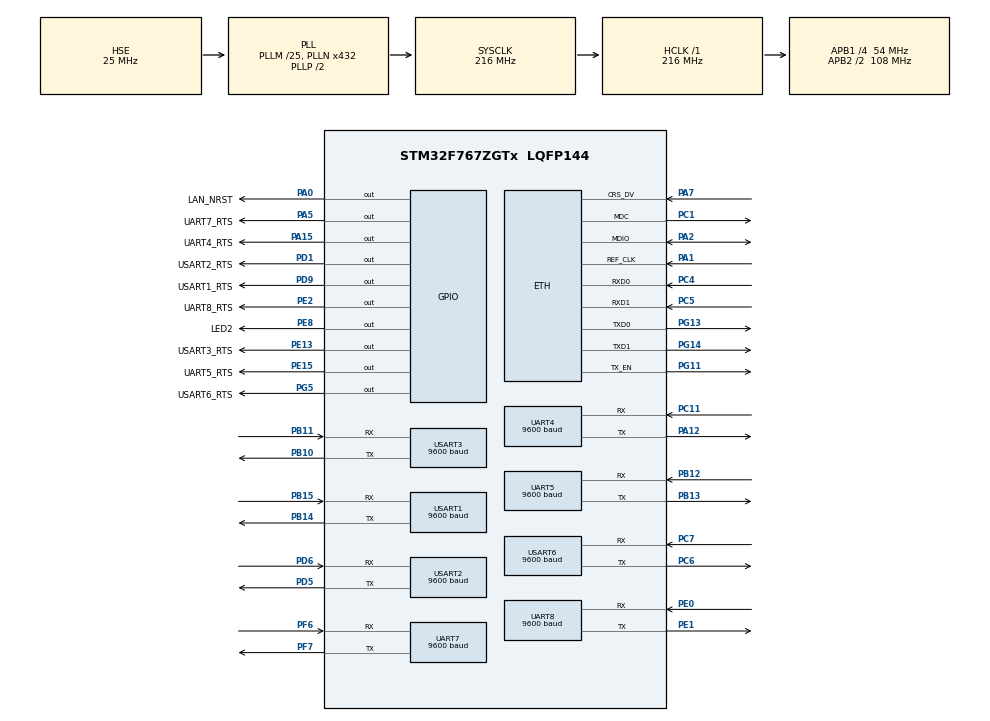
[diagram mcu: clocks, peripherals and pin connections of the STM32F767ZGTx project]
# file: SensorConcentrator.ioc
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CORTEX_M7.ART_ACCELERATOR_ENABLE=1
CORTEX_M7.AccessPermission_Spec=MPU_REGION_FULL_ACCESS
CORTEX_M7.BaseAddress_Spec=0x20000000
CORTEX_M7.CPU_DCache=Enabled
CORTEX_M7.CPU_ICache=Enabled
CORTEX_M7.DisableExec_Spec=MPU_INSTRUCTION_ACCESS_ENABLE
CORTEX_M7.Enable_S-Cortex_Memory_Protection_Unit_Region1_Settings_S=__NULL
CORTEX_M7.Enable_S-Cortex_Memory_Protection_Unit_Region2_Settings_S=__NULL
CORTEX_M7.IsBufferable_Spec=MPU_ACCESS_NOT_BUFFERABLE
CORTEX_M7.IsCacheable_Spec=MPU_ACCESS_NOT_CACHEABLE
CORTEX_M7.IsShareable_Spec=MPU_ACCESS_SHAREABLE
CORTEX_M7.Size_Spec=MPU_REGION_SIZE_512KB
CORTEX_M7.SubRegionDisable_Spec=0x00
CORTEX_M7.TypeExtField_Spec=MPU_TEX_LEVEL1
CORTEX_M7.default_mode_Activation=1
Dma.Request0=USART1_RX
Dma.Request1=USART1_TX
Dma.Request10=UART5_RX
Dma.Request11=UART5_TX
Dma.Request2=USART2_RX
Dma.Request3=USART2_TX
Dma.Request4=USART3_RX
Dma.Request5=USART3_TX
Dma.Request6=USART6_RX
Dma.Request7=USART6_TX
Dma.Request8=UART4_RX
Dma.Request9=UART4_TX
Dma.UART4_RX.8.Direction=DMA_PERIPH_TO_MEMORY
Dma.UART4_RX.8.FIFOMode=DMA_FIFOMODE_DISABLE
Dma.UART4_RX.8.Instance=DMA1_Stream2
Dma.UART4_RX.8.MemDataAlignment=DMA_MDATAALIGN_BYTE
Dma.UART4_RX.8.MemInc=DMA_MINC_ENABLE
Dma.UART4_RX.8.Mode=DMA_CIRCULAR
Dma.UART4_RX.8.PeriphDataAlignment=DMA_PDATAALIGN_BYTE
Dma.UART4_RX.8.PeriphInc=DMA_PINC_DISABLE
Dma.UART4_RX.8.Priority=DMA_PRIORITY_LOW
Dma.UART4_TX.9.Direction=DMA_MEMORY_TO_PERIPH
Dma.UART4_TX.9.FIFOMode=DMA_FIFOMODE_DISABLE
Dma.UART4_TX.9.Instance=DMA1_Stream4
Dma.UART4_TX.9.MemDataAlignment=DMA_MDATAALIGN_BYTE
Dma.UART4_TX.9.MemInc=DMA_MINC_ENABLE
Dma.UART4_TX.9.Mode=DMA_NORMAL
Dma.UART4_TX.9.PeriphDataAlignment=DMA_PDATAALIGN_BYTE
Dma.UART4_TX.9.PeriphInc=DMA_PINC_DISABLE
Dma.UART4_TX.9.Priority=DMA_PRIORITY_LOW
Dma.UART5_RX.10.Direction=DMA_PERIPH_TO_MEMORY
Dma.UART5_RX.10.FIFOMode=DMA_FIFOMODE_DISABLE
Dma.UART5_RX.10.Instance=DMA1_Stream0
Dma.UART5_RX.10.MemDataAlignment=DMA_MDATAALIGN_BYTE
Dma.UART5_RX.10.MemInc=DMA_MINC_ENABLE
Dma.UART5_RX.10.Mode=DMA_CIRCULAR
Dma.UART5_RX.10.PeriphDataAlignment=DMA_PDATAALIGN_BYTE
Dma.UART5_RX.10.PeriphInc=DMA_PINC_DISABLE
Dma.UART5_RX.10.Priority=DMA_PRIORITY_LOW
Dma.UART5_TX.11.Direction=DMA_MEMORY_TO_PERIPH
Dma.UART5_TX.11.FIFOMode=DMA_FIFOMODE_DISABLE
Dma.UART5_TX.11.Instance=DMA1_Stream7
Dma.UART5_TX.11.MemDataAlignment=DMA_MDATAALIGN_BYTE
Dma.UART5_TX.11.MemInc=DMA_MINC_ENABLE
Dma.UART5_TX.11.Mode=DMA_NORMAL
Dma.UART5_TX.11.PeriphDataAlignment=DMA_PDATAALIGN_BYTE
Dma.UART5_TX.11.PeriphInc=DMA_PINC_DISABLE
Dma.UART5_TX.11.Priority=DMA_PRIORITY_LOW
Dma.USART1_RX.0.Direction=DMA_PERIPH_TO_MEMORY
Dma.USART1_RX.0.FIFOMode=DMA_FIFOMODE_DISABLE
Dma.USART1_RX.0.Instance=DMA2_Stream2
Dma.USART1_RX.0.MemDataAlignment=DMA_MDATAALIGN_BYTE
Dma.USART1_RX.0.MemInc=DMA_MINC_ENABLE
Dma.USART1_RX.0.Mode=DMA_CIRCULAR
Dma.USART1_RX.0.PeriphDataAlignment=DMA_PDATAALIGN_BYTE
Dma.USART1_RX.0.PeriphInc=DMA_PINC_DISABLE
Dma.USART1_RX.0.Priority=DMA_PRIORITY_LOW
Dma.USART1_TX.1.Direction=DMA_MEMORY_TO_PERIPH
Dma.USART1_TX.1.FIFOMode=DMA_FIFOMODE_DISABLE
Dma.USART1_TX.1.Instance=DMA2_Stream7
Dma.USART1_TX.1.MemDataAlignment=DMA_MDATAALIGN_BYTE
Dma.USART1_TX.1.MemInc=DMA_MINC_ENABLE
Dma.USART1_TX.1.Mode=DMA_NORMAL
Dma.USART1_TX.1.PeriphDataAlignment=DMA_PDATAALIGN_BYTE
Dma.USART1_TX.1.PeriphInc=DMA_PINC_DISABLE
Dma.USART1_TX.1.Priority=DMA_PRIORITY_LOW
Dma.USART2_RX.2.Direction=DMA_PERIPH_TO_MEMORY
Dma.USART2_RX.2.FIFOMode=DMA_FIFOMODE_DISABLE
Dma.USART2_RX.2.Instance=DMA1_Stream5
Dma.USART2_RX.2.MemDataAlignment=DMA_MDATAALIGN_BYTE
Dma.USART2_RX.2.MemInc=DMA_MINC_ENABLE
Dma.USART2_RX.2.Mode=DMA_CIRCULAR
Dma.USART2_RX.2.PeriphDataAlignment=DMA_PDATAALIGN_BYTE
Dma.USART2_RX.2.PeriphInc=DMA_PINC_DISABLE
Dma.USART2_RX.2.Priority=DMA_PRIORITY_LOW
Dma.USART2_TX.3.Direction=DMA_MEMORY_TO_PERIPH
Dma.USART2_TX.3.FIFOMode=DMA_FIFOMODE_DISABLE
Dma.USART2_TX.3.Instance=DMA1_Stream6
Dma.USART2_TX.3.MemDataAlignment=DMA_MDATAALIGN_BYTE
Dma.USART2_TX.3.MemInc=DMA_MINC_ENABLE
Dma.USART2_TX.3.Mode=DMA_NORMAL
Dma.USART2_TX.3.PeriphDataAlignment=DMA_PDATAALIGN_BYTE
Dma.USART2_TX.3.PeriphInc=DMA_PINC_DISABLE
Dma.USART2_TX.3.Priority=DMA_PRIORITY_LOW
Dma.USART3_RX.4.Direction=DMA_PERIPH_TO_MEMORY
Dma.USART3_RX.4.FIFOMode=DMA_FIFOMODE_DISABLE
Dma.USART3_RX.4.Instance=DMA1_Stream1
Dma.USART3_RX.4.MemDataAlignment=DMA_MDATAALIGN_BYTE
Dma.USART3_RX.4.MemInc=DMA_MINC_ENABLE
Dma.USART3_RX.4.Mode=DMA_CIRCULAR
Dma.USART3_RX.4.PeriphDataAlignment=DMA_PDATAALIGN_BYTE
Dma.USART3_RX.4.PeriphInc=DMA_PINC_DISABLE
Dma.USART3_RX.4.Priority=DMA_PRIORITY_LOW
Dma.USART3_TX.5.Direction=DMA_MEMORY_TO_PERIPH
Dma.USART3_TX.5.FIFOMode=DMA_FIFOMODE_DISABLE
Dma.USART3_TX.5.Instance=DMA1_Stream3
Dma.USART3_TX.5.MemDataAlignment=DMA_MDATAALIGN_BYTE
Dma.USART3_TX.5.MemInc=DMA_MINC_ENABLE
Dma.USART3_TX.5.Mode=DMA_NORMAL
Dma.USART3_TX.5.PeriphDataAlignment=DMA_PDATAALIGN_BYTE
Dma.USART3_TX.5.PeriphInc=DMA_PINC_DISABLE
Dma.USART3_TX.5.Priority=DMA_PRIORITY_LOW
Dma.USART6_RX.6.Direction=DMA_PERIPH_TO_MEMORY
Dma.USART6_RX.6.FIFOMode=DMA_FIFOMODE_DISABLE
Dma.USART6_RX.6.Instance=DMA2_Stream1
Dma.USART6_RX.6.MemDataAlignment=DMA_MDATAALIGN_BYTE
Dma.USART6_RX.6.MemInc=DMA_MINC_ENABLE
Dma.USART6_RX.6.Mode=DMA_CIRCULAR
Dma.USART6_RX.6.PeriphDataAlignment=DMA_PDATAALIGN_BYTE
Dma.USART6_RX.6.PeriphInc=DMA_PINC_DISABLE
Dma.USART6_RX.6.Priority=DMA_PRIORITY_LOW
Dma.USART6_TX.7.Direction=DMA_MEMORY_TO_PERIPH
Dma.USART6_TX.7.FIFOMode=DMA_FIFOMODE_DISABLE
Dma.USART6_TX.7.Instance=DMA2_Stream6
Dma.USART6_TX.7.MemDataAlignment=DMA_MDATAALIGN_BYTE
Dma.USART6_TX.7.MemInc=DMA_MINC_ENABLE
Dma.USART6_TX.7.Mode=DMA_NORMAL
Dma.USART6_TX.7.PeriphDataAlignment=DMA_PDATAALIGN_BYTE
Dma.USART6_TX.7.PeriphInc=DMA_PINC_DISABLE
Dma.USART6_TX.7.Priority=DMA_PRIORITY_LOW
ETH.ETH_RX_DESC_CNT=8
ETH.ETH_TX_DESC_CNT=8
ETH.MediaInterface=HAL_ETH_RMII_MODE
ETH.RxDescAddress=0x20010200
ETH.TxDescAddress=0x20010000
FREERTOS.INCLUDE_pcTaskGetTaskName=1
FREERTOS.INCLUDE_uxTaskGetStackHighWaterMark=1
FREERTOS.INCLUDE_uxTaskGetStackHighWaterMark2=1
FREERTOS.INCLUDE_vTaskDelayUntil=1
FREERTOS.INCLUDE_xTaskGetCurrentTaskHandle=1
FREERTOS.Tasks01=defaultTask,0,1024,StartDefaultTask,Default,NULL,Dynamic,NULL,NULL
FREERTOS.configCHECK_FOR_STACK_OVERFLOW=2
FREERTOS.configENABLE_FPU=1
FREERTOS.configMAX_PRIORITIES=20
FREERTOS.configMINIMAL_STACK_SIZE=256
FREERTOS.configQUEUE_REGISTRY_SIZE=16
FREERTOS.configTIMER_QUEUE_LENGTH=16
FREERTOS.configTIMER_TASK_PRIORITY=4
FREERTOS.configTOTAL_HEAP_SIZE=102400
FREERTOS.configUSE_COUNTING_SEMAPHORES=1
FREERTOS.configUSE_MALLOC_FAILED_HOOK=1
FREERTOS.configUSE_RECURSIVE_MUTEXES=1
FREERTOS.configUSE_TIMERS=1
FREERTOS.configUSE_TRACE_FACILITY=1
IWDG.Prescaler=IWDG_PRESCALER_128
LWIP.BSP.number=1
LWIP.DEFAULT_THREAD_STACKSIZE=2048
LWIP.ETH_RX_BUFFER_CNT=32
LWIP.LWIP_DHCP=0
LWIP.LWIP_RAM_HEAP_POINTER=0x00000000
LWIP.LWIP_SNTP=1
LWIP.LWIP_TFTP=1
LWIP.MEMP_NUM_PBUF=64
LWIP.MEMP_NUM_TCP_SEG=24
LWIP.MEM_SIZE=24*1024
LWIP.PBUF_POOL_SIZE=32
LWIP.TCPIP_THREAD_STACKSIZE=4096
LWIP.TCP_SND_QUEUELEN=24
LWIP.Version=v2.1.2_Cube
LWIP0.BSP.STBoard=false
LWIP0.BSP.api=BSP_COMPONENT_DRIVER
LWIP0.BSP.component=LAN8742
LWIP0.BSP.instance=LAN8742
LWIP0.BSP.name=Driver_PHY
LWIP0.BSP.semaphore=S_LAN8742
LWIP0.BSP.solution=LAN8742
Mcu.Family=STM32F7
Mcu.Name=STM32F767ZGTx
Mcu.Package=LQFP144
NVIC.DMA1_Stream0_IRQn=true\:5\:0\:false\:false\:true\:true\:false\:true\:true
NVIC.DMA1_Stream1_IRQn=true\:5\:0\:false\:false\:true\:true\:false\:true\:true
NVIC.DMA1_Stream2_IRQn=true\:5\:0\:false\:false\:true\:true\:false\:true\:true
NVIC.DMA1_Stream3_IRQn=true\:5\:0\:false\:false\:true\:true\:false\:true\:true
NVIC.DMA1_Stream4_IRQn=true\:5\:0\:false\:false\:true\:true\:false\:true\:true
NVIC.DMA1_Stream5_IRQn=true\:5\:0\:false\:false\:true\:true\:false\:true\:true
NVIC.DMA1_Stream6_IRQn=true\:5\:0\:false\:false\:true\:true\:false\:true\:true
NVIC.DMA1_Stream7_IRQn=true\:5\:0\:false\:false\:true\:true\:false\:true\:true
NVIC.DMA2_Stream1_IRQn=true\:5\:0\:false\:false\:true\:true\:false\:true\:true
NVIC.DMA2_Stream2_IRQn=true\:5\:0\:false\:false\:true\:true\:false\:true\:true
NVIC.DMA2_Stream6_IRQn=true\:5\:0\:false\:false\:true\:true\:false\:true\:true
NVIC.DMA2_Stream7_IRQn=true\:5\:0\:false\:false\:true\:true\:false\:true\:true
NVIC.ETH_IRQn=true\:5\:0\:false\:false\:true\:true\:true\:true\:true
NVIC.PriorityGroup=NVIC_PRIORITYGROUP_4
NVIC.TIM7_IRQn=true\:15\:0\:false\:false\:true\:false\:false\:true\:true
NVIC.TimeBase=TIM7_IRQn
NVIC.TimeBaseIP=TIM7
NVIC.UART4_IRQn=true\:5\:0\:false\:false\:true\:true\:false\:true\:true
NVIC.UART5_IRQn=true\:5\:0\:false\:false\:true\:true\:false\:true\:true
NVIC.UART7_IRQn=true\:5\:0\:false\:false\:true\:true\:true\:true\:true
NVIC.UART8_IRQn=true\:5\:0\:false\:false\:true\:true\:false\:true\:true
NVIC.USART1_IRQn=true\:5\:0\:false\:false\:true\:true\:true\:true\:true
NVIC.USART2_IRQn=true\:5\:0\:false\:false\:true\:true\:false\:true\:true
NVIC.USART3_IRQn=true\:5\:0\:false\:false\:true\:true\:false\:true\:true
NVIC.USART6_IRQn=true\:5\:0\:false\:false\:true\:true\:false\:true\:true
PA0/WKUP.GPIO_Label=LAN_NRST
PA0/WKUP.GPIO_Speed=GPIO_SPEED_FREQ_LOW
PA0/WKUP.PinState=GPIO_PIN_SET
PA0/WKUP.Signal=GPIO_Output
PA1.Mode=RMII
PA1.Signal=ETH_REF_CLK
PA12.Mode=Asynchronous
PA12.Signal=UART4_TX
PA13.GPIO_Label=SWDIO
PA13.Mode=Serial_Wire
PA13.Signal=SYS_JTMS-SWDIO
PA14.GPIO_Label=SWCLK
PA14.Mode=Serial_Wire
PA14.Signal=SYS_JTCK-SWCLK
PA15.GPIO_Label=UART4_RTS
PA15.Signal=GPIO_Output
PA2.Mode=RMII
PA2.Signal=ETH_MDIO
PA5.GPIO_Label=UART7_RTS
PA5.Signal=GPIO_Output
PA7.Mode=RMII
PA7.Signal=ETH_CRS_DV
PB10.Mode=Asynchronous
PB10.Signal=USART3_TX
PB11.Mode=Asynchronous
PB11.Signal=USART3_RX
PB12.Mode=Asynchronous
PB12.Signal=UART5_RX
PB13.Mode=Asynchronous
PB13.Signal=UART5_TX
PB14.Mode=Asynchronous
PB14.Signal=USART1_TX
PB15.Mode=Asynchronous
PB15.Signal=USART1_RX
PC1.Mode=RMII
PC1.Signal=ETH_MDC
PC11.Mode=Asynchronous
PC11.Signal=UART4_RX
PC14/OSC32_IN.Mode=LSE-External-Oscillator
PC14/OSC32_IN.Signal=RCC_OSC32_IN
PC15/OSC32_OUT.Mode=LSE-External-Oscillator
PC15/OSC32_OUT.Signal=RCC_OSC32_OUT
PC4.Mode=RMII
PC4.Signal=ETH_RXD0
PC5.Mode=RMII
PC5.Signal=ETH_RXD1
PC6.Mode=Asynchronous
PC6.Signal=USART6_TX
PC7.Mode=Asynchronous
PC7.Signal=USART6_RX
PD1.GPIO_Label=USART2_RTS
PD1.Signal=GPIO_Output
PD5.Mode=Asynchronous
PD5.Signal=USART2_TX
PD6.Mode=Asynchronous
PD6.Signal=USART2_RX
PD9.GPIO_Label=USART1_RTS
PD9.Signal=GPIO_Output
PE0.Mode=Asynchronous
PE0.Signal=UART8_RX
PE1.Mode=Asynchronous
PE1.Signal=UART8_TX
PE13.GPIO_Label=USART3_RTS
PE13.Signal=GPIO_Output
PE15.GPIO_Label=UART5_RTS
PE15.Signal=GPIO_Output
PE2.GPIO_Label=UART8_RTS
PE2.Signal=GPIO_Output
PE8.GPIO_Label=LED2
PE8.Signal=GPIO_Output
PF6.Mode=Asynchronous
PF6.Signal=UART7_RX
PF7.Mode=Asynchronous
PF7.Signal=UART7_TX
PG11.Mode=RMII
PG11.Signal=ETH_TX_EN
PG13.Mode=RMII
PG13.Signal=ETH_TXD0
PG14.Mode=RMII
PG14.Signal=ETH_TXD1
PG5.GPIO_Label=USART6_RTS
PG5.Signal=GPIO_Output
PH0/OSC_IN.Mode=HSE-External-Oscillator
PH0/OSC_IN.Signal=RCC_OSC_IN
PH1/OSC_OUT.Mode=HSE-External-Oscillator
PH1/OSC_OUT.Signal=RCC_OSC_OUT
ProjectManager.HeapSize=0x1200
ProjectManager.StackSize=0x1000
ProjectManager.TargetToolchain=CMake
RCC.AHBFreq_Value=216000000
RCC.APB1CLKDivider=RCC_HCLK_DIV4
RCC.APB1Freq_Value=54000000
RCC.APB1TimFreq_Value=108000000
RCC.APB2CLKDivider=RCC_HCLK_DIV2
RCC.APB2Freq_Value=108000000
RCC.APB2TimFreq_Value=216000000
RCC.CortexFreq_Value=216000000
RCC.HCLKFreq_Value=216000000
RCC.HSE_VALUE=25000000
RCC.HSI_VALUE=16000000
RCC.PLLM=25
RCC.PLLN=432
RCC.PLLSourceVirtual=RCC_PLLSOURCE_HSE
RCC.SYSCLKFreq_VALUE=216000000
RCC.SYSCLKSource=RCC_SYSCLKSOURCE_PLLCLK
RCC.USBFreq_Value=216000000
RCC.VCOOutputFreq_Value=432000000
RTC.Month=RTC_MONTH_SEPTEMBER
RTC.WeekDay=RTC_WEEKDAY_FRIDAY
RTC.Year=26
UART4.BaudRate=9600
UART5.BaudRate=9600
UART7.BaudRate=9600
UART8.BaudRate=9600
USART1.BaudRate=9600
USART1.VirtualMode-Asynchronous=VM_ASYNC
USART2.BaudRate=9600
USART2.VirtualMode-Asynchronous=VM_ASYNC
USART3.BaudRate=9600
USART3.VirtualMode-Asynchronous=VM_ASYNC
USART6.BaudRate=9600
USART6.VirtualMode-Asynchronous=VM_ASYNC
VP_FREERTOS_VS_CMSIS_V1.Mode=CMSIS_V1
VP_IWDG_VS_IWDG.Mode=IWDG_Activate
VP_LWIP_VS_Enabled.Mode=Enabled
VP_RTC_VS_RTC_Activate.Mode=RTC_Enabled
VP_RTC_VS_RTC_Calendar.Mode=RTC_Calendar
VP_SYS_VS_tim7.Mode=TIM7
board=custom

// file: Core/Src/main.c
/* USER CODE BEGIN Header */
/**
  ******************************************************************************
  * @file           : main.c
  * @brief          : Main program body
  ******************************************************************************
  * @attention
  *
  * Copyright (c) 2026 STMicroelectronics.
  * All rights reserved.
  *
  * This software is licensed under terms that can be found in the LICENSE file
  * in the root directory of this software component.
  * If no LICENSE file comes with this software, it is provided AS-IS.
  *
  ******************************************************************************
  */
/* USER CODE END Header */
#include "main.h"
#include "cmsis_os.h"
#include "dma.h"
#include "iwdg.h"
#include "lwip.h"
#include "rtc.h"
#include "usart.h"
#include "gpio.h"

/* USER CODE BEGIN Includes */
#include "debug_uart.h"
#include "cJSON.h"
/* USER CODE END Includes */

void SystemClock_Config(void);
static void MPU_Config(void);
void MX_FREERTOS_Init(void);

int main(void)
{

  /* MPU Configuration--------------------------------------------------------*/
  MPU_Config();

  /* Enable the CPU Cache */

  /* Enable I-Cache---------------------------------------------------------*/
  SCB_EnableICache();

  /* Enable D-Cache---------------------------------------------------------*/
  SCB_EnableDCache();

  /* MCU Configuration--------------------------------------------------------*/

  /* Reset of all peripherals, Initializes the Flash interface and the Systick. */
  HAL_Init();

  /* Configure the system clock */
  SystemClock_Config();

  /* Initialize all configured peripherals */
  MX_GPIO_Init();
  MX_DMA_Init();
  MX_UART4_Init();
  MX_UART5_Init();
  MX_UART7_Init();
  MX_UART8_Init();
  MX_USART1_UART_Init();
  MX_USART2_UART_Init();
  MX_USART3_UART_Init();
  MX_USART6_UART_Init();
  MX_IWDG_Init();
  MX_RTC_Init();
  /* USER CODE BEGIN 2 */
  /* 临时调试口：上电即初始化，不依赖任何任务是否创建成功 */
  DebugUart_Init();
  cJSON_Init_FreeRTOS_Heap();
  /* USER CODE END 2 */

  /* Call init function for freertos objects (in cmsis_os2.c) */
  MX_FREERTOS_Init();

  /* Start scheduler */
  osKernelStart();

  /* We should never get here as control is now taken by the scheduler */

  /* Infinite loop */
  while (1)
  {

  }
}

void SystemClock_Config(void)
{
  RCC_OscInitTypeDef RCC_OscInitStruct = {0};
  RCC_ClkInitTypeDef RCC_ClkInitStruct = {0};

  /** Configure LSE Drive Capability
  */
  HAL_PWR_EnableBkUpAccess();

  /** Configure the main internal regulator output voltage
  */
  __HAL_RCC_PWR_CLK_ENABLE();
  __HAL_PWR_VOLTAGESCALING_CONFIG(PWR_REGULATOR_VOLTAGE_SCALE1);

  /** Initializes the RCC Oscillators according to the specified parameters
  * in the RCC_OscInitTypeDef structure.
  */
  RCC_OscInitStruct.OscillatorType = RCC_OSCILLATORTYPE_LSI|RCC_OSCILLATORTYPE_HSE;
  RCC_OscInitStruct.HSEState = RCC_HSE_ON;
  RCC_OscInitStruct.LSIState = RCC_LSI_ON;
  RCC_OscInitStruct.PLL.PLLState = RCC_PLL_ON;
  RCC_OscInitStruct.PLL.PLLSource = RCC_PLLSOURCE_HSE;
  RCC_OscInitStruct.PLL.PLLM = 25;
  RCC_OscInitStruct.PLL.PLLN = 432;
  RCC_OscInitStruct.PLL.PLLP = RCC_PLLP_DIV2;
  RCC_OscInitStruct.PLL.PLLQ = 2;
  RCC_OscInitStruct.PLL.PLLR = 2;
  if (HAL_RCC_OscConfig(&RCC_OscInitStruct) != HAL_OK)
  {
    Error_Handler();
  }

  /** Activate the Over-Drive mode
  */
  if (HAL_PWREx_EnableOverDrive() != HAL_OK)
  {
    Error_Handler();
  }

  /** Initializes the CPU, AHB and APB buses clocks
  */
  RCC_ClkInitStruct.ClockType = RCC_CLOCKTYPE_HCLK|RCC_CLOCKTYPE_SYSCLK
                              |RCC_CLOCKTYPE_PCLK1|RCC_CLOCKTYPE_PCLK2;
  RCC_ClkInitStruct.SYSCLKSource = RCC_SYSCLKSOURCE_PLLCLK;
  RCC_ClkInitStruct.AHBCLKDivider = RCC_SYSCLK_DIV1;
  RCC_ClkInitStruct.APB1CLKDivider = RCC_HCLK_DIV4;
  RCC_ClkInitStruct.APB2CLKDivider = RCC_HCLK_DIV2;

  if (HAL_RCC_ClockConfig(&RCC_ClkInitStruct, FLASH_LATENCY_7) != HAL_OK)
  {
    Error_Handler();
  }
}

 /* MPU Configuration */

void MPU_Config(void)
{
  MPU_Region_InitTypeDef MPU_InitStruct = {0};

  /* Disables the MPU */
  HAL_MPU_Disable();

  /** Initializes and configures the Region and the memory to be protected
  */
  MPU_InitStruct.Enable = MPU_REGION_ENABLE;
  MPU_InitStruct.Number = MPU_REGION_NUMBER0;
  MPU_InitStruct.BaseAddress = 0x20000000;
  MPU_InitStruct.Size = MPU_REGION_SIZE_512KB;
  MPU_InitStruct.SubRegionDisable = 0x00;
  MPU_InitStruct.TypeExtField = MPU_TEX_LEVEL1;
  MPU_InitStruct.AccessPermission = MPU_REGION_FULL_ACCESS;
  MPU_InitStruct.DisableExec = MPU_INSTRUCTION_ACCESS_ENABLE;
  MPU_InitStruct.IsShareable = MPU_ACCESS_SHAREABLE;
  MPU_InitStruct.IsCacheable = MPU_ACCESS_NOT_CACHEABLE;
  MPU_InitStruct.IsBufferable = MPU_ACCESS_NOT_BUFFERABLE;

  HAL_MPU_ConfigRegion(&MPU_InitStruct);
  /* Enables the MPU */
  HAL_MPU_Enable(MPU_PRIVILEGED_DEFAULT);

}

void HAL_TIM_PeriodElapsedCallback(TIM_HandleTypeDef *htim)
{
  if (htim->Instance == TIM7)
  {
    HAL_IncTick();
  }
}

void Error_Handler(void)
{
  __disable_irq();
  while (1)
  {
  }
}
